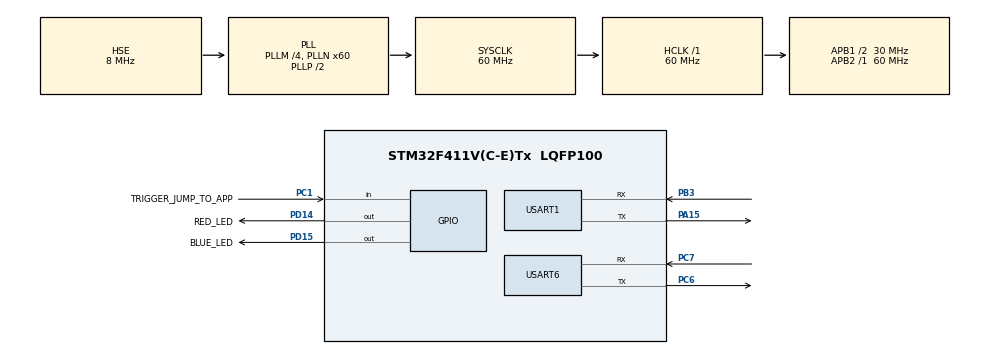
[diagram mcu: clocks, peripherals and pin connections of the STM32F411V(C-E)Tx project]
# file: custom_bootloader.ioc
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Mcu.Family=STM32F4
Mcu.Name=STM32F411V(C-E)Tx
Mcu.Package=LQFP100
NVIC.PriorityGroup=NVIC_PRIORITYGROUP_4
PA13.Mode=Serial_Wire
PA13.Signal=SYS_JTMS-SWDIO
PA14.Mode=Serial_Wire
PA14.Signal=SYS_JTCK-SWCLK
PA15.Mode=Asynchronous
PA15.Signal=USART1_TX
PB3.Mode=Asynchronous
PB3.Signal=USART1_RX
PC1.GPIO_Label=TRIGGER_JUMP_TO_APP
PC1.GPIO_PuPd=GPIO_PULLUP
PC1.Signal=GPIO_Input
PC6.Mode=Asynchronous
PC6.Signal=USART6_TX
PC7.Mode=Asynchronous
PC7.Signal=USART6_RX
PD14.GPIO_Label=RED_LED
PD14.GPIO_PuPd=GPIO_PULLUP
PD14.Signal=GPIO_Output
PD15.GPIO_Label=BLUE_LED
PD15.GPIO_PuPd=GPIO_PULLUP
PD15.Signal=GPIO_Output
PH0\ -\ OSC_IN.Mode=HSE-External-Oscillator
PH0\ -\ OSC_IN.Signal=RCC_OSC_IN
PH1\ -\ OSC_OUT.Mode=HSE-External-Oscillator
PH1\ -\ OSC_OUT.Signal=RCC_OSC_OUT
ProjectManager.HeapSize=0x200
ProjectManager.StackSize=0x400
ProjectManager.TargetToolchain=STM32CubeIDE
RCC.48MHZClocksFreq_Value=30000000
RCC.AHBFreq_Value=60000000
RCC.APB1CLKDivider=RCC_HCLK_DIV2
RCC.APB1Freq_Value=30000000
RCC.APB1TimFreq_Value=60000000
RCC.APB2Freq_Value=60000000
RCC.APB2TimFreq_Value=60000000
RCC.CortexFreq_Value=60000000
RCC.HCLKFreq_Value=60000000
RCC.HSE_VALUE=8000000
RCC.HSI_VALUE=16000000
RCC.LSE_VALUE=32768
RCC.PLLM=4
RCC.PLLN=60
RCC.PLLSourceVirtual=RCC_PLLSOURCE_HSE
RCC.SYSCLKFreq_VALUE=60000000
RCC.SYSCLKSource=RCC_SYSCLKSOURCE_PLLCLK
RCC.VCOOutputFreq_Value=120000000
USART1.VirtualMode=VM_ASYNC
USART6.VirtualMode=VM_ASYNC
VP_CRC_VS_CRC.Mode=CRC_Activate
board=custom

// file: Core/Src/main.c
/* USER CODE BEGIN Header */
/**
  ******************************************************************************
  * @file           : main.c
  * @brief          : Main program body
  ******************************************************************************
  * @attention
  *
  * Copyright (c) 2025 STMicroelectronics.
  * All rights reserved.
  *
  * This software is licensed under terms that can be found in the LICENSE file
  * in the root directory of this software component.
  * If no LICENSE file comes with this software, it is provided AS-IS.
  *
  ******************************************************************************
  */
/* USER CODE END Header */
#include "main.h"

/* USER CODE BEGIN Includes */

#include "uart_command.h"
#include "uart_log.h"
/* USER CODE END Includes */

CRC_HandleTypeDef hcrc;

UART_HandleTypeDef huart1;
UART_HandleTypeDef huart6;

void SystemClock_Config(void);
static void MX_GPIO_Init(void);
static void MX_USART6_UART_Init(void);
static void MX_CRC_Init(void);
static void MX_USART1_UART_Init(void);

int main(void)
{

  /* MCU Configuration--------------------------------------------------------*/

  /* Reset of all peripherals, Initializes the Flash interface and the Systick. */
  HAL_Init();

  /* Configure the system clock */
  SystemClock_Config();

  /* Initialize all configured peripherals */
  MX_GPIO_Init();
  MX_USART6_UART_Init();
  MX_CRC_Init();
  MX_USART1_UART_Init();
  /* USER CODE BEGIN 2 */
  if ( HAL_GPIO_ReadPin(TRIGGER_JUMP_TO_APP_GPIO_Port,TRIGGER_JUMP_TO_APP_Pin) == GPIO_PIN_RESET)
  {
	  printmsg("Jump to update new firmware \r\n");
	  bootloader_uart_read_data();
  }
  else
  {
	  printmsg("Jump to app without update new firmware \r\n");
	  bootloader_jump_to_user_app();

  }
  /* USER CODE END 2 */

  /* Infinite loop */
  while (1)
  {

  }
}

void SystemClock_Config(void)
{
  RCC_OscInitTypeDef RCC_OscInitStruct = {0};
  RCC_ClkInitTypeDef RCC_ClkInitStruct = {0};

  /** Configure the main internal regulator output voltage
  */
  __HAL_RCC_PWR_CLK_ENABLE();
  __HAL_PWR_VOLTAGESCALING_CONFIG(PWR_REGULATOR_VOLTAGE_SCALE1);

  /** Initializes the RCC Oscillators according to the specified parameters
  * in the RCC_OscInitTypeDef structure.
  */
  RCC_OscInitStruct.OscillatorType = RCC_OSCILLATORTYPE_HSE;
  RCC_OscInitStruct.HSEState = RCC_HSE_ON;
  RCC_OscInitStruct.PLL.PLLState = RCC_PLL_ON;
  RCC_OscInitStruct.PLL.PLLSource = RCC_PLLSOURCE_HSE;
  RCC_OscInitStruct.PLL.PLLM = 4;
  RCC_OscInitStruct.PLL.PLLN = 60;
  RCC_OscInitStruct.PLL.PLLP = RCC_PLLP_DIV2;
  RCC_OscInitStruct.PLL.PLLQ = 4;
  if (HAL_RCC_OscConfig(&RCC_OscInitStruct) != HAL_OK)
  {
    Error_Handler();
  }

  /** Initializes the CPU, AHB and APB buses clocks
  */
  RCC_ClkInitStruct.ClockType = RCC_CLOCKTYPE_HCLK|RCC_CLOCKTYPE_SYSCLK
                              |RCC_CLOCKTYPE_PCLK1|RCC_CLOCKTYPE_PCLK2;
  RCC_ClkInitStruct.SYSCLKSource = RCC_SYSCLKSOURCE_PLLCLK;
  RCC_ClkInitStruct.AHBCLKDivider = RCC_SYSCLK_DIV1;
  RCC_ClkInitStruct.APB1CLKDivider = RCC_HCLK_DIV2;
  RCC_ClkInitStruct.APB2CLKDivider = RCC_HCLK_DIV1;

  if (HAL_RCC_ClockConfig(&RCC_ClkInitStruct, FLASH_LATENCY_1) != HAL_OK)
  {
    Error_Handler();
  }
}

static void MX_CRC_Init(void)
{

  /* USER CODE BEGIN CRC_Init 0 */
	__HAL_RCC_CRC_CLK_ENABLE();
  /* USER CODE END CRC_Init 0 */

  hcrc.Instance = CRC;
  if (HAL_CRC_Init(&hcrc) != HAL_OK)
  {
    Error_Handler();
  }

}

static void MX_USART1_UART_Init(void)
{

  huart1.Instance = USART1;
  huart1.Init.BaudRate = 115200;
  huart1.Init.WordLength = UART_WORDLENGTH_8B;
  huart1.Init.StopBits = UART_STOPBITS_1;
  huart1.Init.Parity = UART_PARITY_NONE;
  huart1.Init.Mode = UART_MODE_TX_RX;
  huart1.Init.HwFlowCtl = UART_HWCONTROL_NONE;
  huart1.Init.OverSampling = UART_OVERSAMPLING_16;
  if (HAL_UART_Init(&huart1) != HAL_OK)
  {
    Error_Handler();
  }

}

static void MX_USART6_UART_Init(void)
{

  huart6.Instance = USART6;
  huart6.Init.BaudRate = 115200;
  huart6.Init.WordLength = UART_WORDLENGTH_8B;
  huart6.Init.StopBits = UART_STOPBITS_1;
  huart6.Init.Parity = UART_PARITY_NONE;
  huart6.Init.Mode = UART_MODE_TX_RX;
  huart6.Init.HwFlowCtl = UART_HWCONTROL_NONE;
  huart6.Init.OverSampling = UART_OVERSAMPLING_16;
  if (HAL_UART_Init(&huart6) != HAL_OK)
  {
    Error_Handler();
  }

}

static void MX_GPIO_Init(void)
{
  GPIO_InitTypeDef GPIO_InitStruct = {0};

  /* GPIO Ports Clock Enable */
  __HAL_RCC_GPIOH_CLK_ENABLE();
  __HAL_RCC_GPIOC_CLK_ENABLE();
  __HAL_RCC_GPIOD_CLK_ENABLE();
  __HAL_RCC_GPIOA_CLK_ENABLE();
  __HAL_RCC_GPIOB_CLK_ENABLE();

  /*Configure GPIO pin Output Level */
  HAL_GPIO_WritePin(GPIOD, RED_LED_Pin|BLUE_LED_Pin, GPIO_PIN_RESET);

  /*Configure GPIO pin : TRIGGER_JUMP_TO_APP_Pin */
  GPIO_InitStruct.Pin = TRIGGER_JUMP_TO_APP_Pin;
  GPIO_InitStruct.Mode = GPIO_MODE_INPUT;
  GPIO_InitStruct.Pull = GPIO_PULLUP;
  HAL_GPIO_Init(TRIGGER_JUMP_TO_APP_GPIO_Port, &GPIO_InitStruct);

  /*Configure GPIO pins : RED_LED_Pin BLUE_LED_Pin */
  GPIO_InitStruct.Pin = RED_LED_Pin|BLUE_LED_Pin;
  GPIO_InitStruct.Mode = GPIO_MODE_OUTPUT_PP;
  GPIO_InitStruct.Pull = GPIO_PULLUP;
  GPIO_InitStruct.Speed = GPIO_SPEED_FREQ_LOW;
  HAL_GPIO_Init(GPIOD, &GPIO_InitStruct);

}

void Error_Handler(void)
{
  __disable_irq();
  while (1)
  {
  }
}
